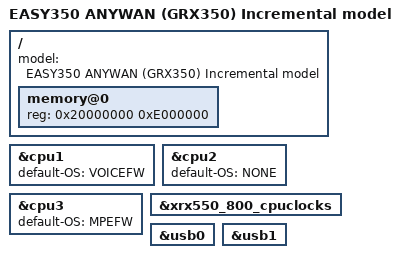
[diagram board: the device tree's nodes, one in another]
/dts-v1/;

/*****************************************************************
** Include a chip configuration file                             
*****************************************************************/
/include/ "xrx500_stripped.dtsi"
/ {

	model = "EASY350 ANYWAN (GRX350) Incremental model";

	memory@0 {
		device_type = "memory";
		reg = <0x20000000 0xE000000>;
	};
};
/******************************************************************************
** Model configuration: Arrange specific FW to run on VPEs. 
******************************************************************************/
/* use CPU1 for voice firmware */
&cpu1 {
	default-OS = "VOICEFW";
};

&cpu2 {
       default-OS = "NONE";
};

/* use CPU3 for MPE firmware */
&cpu3 {
	default-OS = "MPEFW";
};

/******************************************************************************/

/******************************************************************************
** Model configuration: CPU Clock Setting for this model. 
******************************************************************************/
/* configure cpu clock to 800 MHz*/
&xrx550_800_cpuclocks {	
	status = "okay";
};
/******************************************************************************
** Board configuration: Enable USB board configuration.  
******************************************************************************/
&usb0{
	status = "ok";
};
&usb1{
	status = "ok";
};
/*****************************************************************************/


